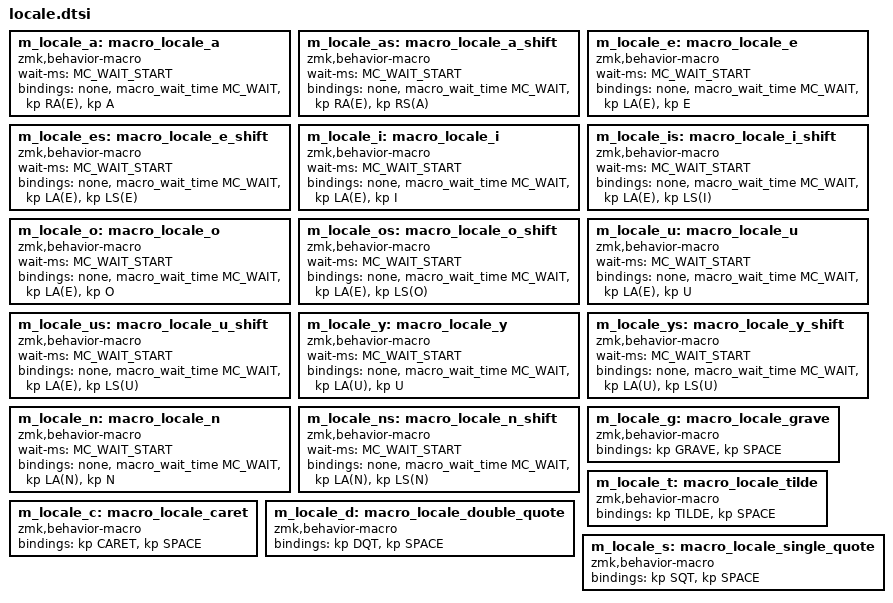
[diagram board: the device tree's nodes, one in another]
// action:     á
m_locale_a: macro_locale_a {
    compatible = "zmk,behavior-macro";
    #binding-cells = <0>;
    wait-ms = <MC_WAIT_START>;
    bindings
        = <&none>
        , <&macro_wait_time MC_WAIT>
        , <&kp RA(E)>
        , <&kp A>;
};

// action:     Á
m_locale_as: macro_locale_a_shift {
    compatible = "zmk,behavior-macro";
    #binding-cells = <0>;
    wait-ms = <MC_WAIT_START>;
    bindings
        = <&none>
        , <&macro_wait_time MC_WAIT>
        , <&kp RA(E)>
        , <&kp RS(A)>;
};

// action:     é
m_locale_e: macro_locale_e {
    compatible = "zmk,behavior-macro";
    #binding-cells = <0>;
    wait-ms = <MC_WAIT_START>;
    bindings
        = <&none>
        , <&macro_wait_time MC_WAIT>
        , <&kp LA(E)>
        , <&kp E>;
};

// action:     É
m_locale_es: macro_locale_e_shift {
    compatible = "zmk,behavior-macro";
    #binding-cells = <0>;
    wait-ms = <MC_WAIT_START>;
    bindings
        = <&none>
        , <&macro_wait_time MC_WAIT>
        , <&kp LA(E)>
        , <&kp LS(E)>;
};

// action:     í
m_locale_i: macro_locale_i {
    compatible = "zmk,behavior-macro";
    #binding-cells = <0>;
    wait-ms = <MC_WAIT_START>;
    bindings
        = <&none>
        , <&macro_wait_time MC_WAIT>
        , <&kp LA(E)>
        , <&kp I>;
};

// action:     Í
m_locale_is: macro_locale_i_shift {
    compatible = "zmk,behavior-macro";
    #binding-cells = <0>;
    wait-ms = <MC_WAIT_START>;
    bindings
        = <&none>
        , <&macro_wait_time MC_WAIT>
        , <&kp LA(E)>
        , <&kp LS(I)>;
};

// action:     ó
m_locale_o: macro_locale_o {
    compatible = "zmk,behavior-macro";
    #binding-cells = <0>;
    wait-ms = <MC_WAIT_START>;
    bindings
        = <&none>
        , <&macro_wait_time MC_WAIT>
        , <&kp LA(E)>
        , <&kp O>;
};

// action:     Ó
m_locale_os: macro_locale_o_shift {
    compatible = "zmk,behavior-macro";
    #binding-cells = <0>;
    wait-ms = <MC_WAIT_START>;
    bindings
        = <&none>
        , <&macro_wait_time MC_WAIT>
        , <&kp LA(E)>
        , <&kp LS(O)>;
};

// action:     ú
m_locale_u: macro_locale_u {
    compatible = "zmk,behavior-macro";
    #binding-cells = <0>;
    wait-ms = <MC_WAIT_START>;
    bindings
        = <&none>
        , <&macro_wait_time MC_WAIT>
        , <&kp LA(E)>
        , <&kp U>;
};

// action:     Ú
m_locale_us: macro_locale_u_shift {
    compatible = "zmk,behavior-macro";
    #binding-cells = <0>;
    wait-ms = <MC_WAIT_START>;

    bindings
        = <&none>
        , <&macro_wait_time MC_WAIT>
        , <&kp LA(E)>
        , <&kp LS(U)>;
};

// action:     ü
m_locale_y: macro_locale_y {
    compatible = "zmk,behavior-macro";
    #binding-cells = <0>;
    wait-ms = <MC_WAIT_START>;
    bindings
        = <&none>
        , <&macro_wait_time MC_WAIT>
        , <&kp LA(U)>
        , <&kp U>;
};

// action:     Ü
m_locale_ys: macro_locale_y_shift {
    compatible = "zmk,behavior-macro";
    #binding-cells = <0>;
    wait-ms = <MC_WAIT_START>;
    bindings
        = <&none>
        , <&macro_wait_time MC_WAIT>
        , <&kp LA(U)>
        , <&kp LS(U)>;
};

// action:     ñ
m_locale_n: macro_locale_n {
    compatible = "zmk,behavior-macro";
    #binding-cells = <0>;
    wait-ms = <MC_WAIT_START>;
    bindings
        = <&none>
        , <&macro_wait_time MC_WAIT>
        , <&kp LA(N)>
        , <&kp N>;
};

// action:     Ñ
m_locale_ns: macro_locale_n_shift {
    compatible = "zmk,behavior-macro";
    #binding-cells = <0>;
    wait-ms = <MC_WAIT_START>;
    bindings
        = <&none>
        , <&macro_wait_time MC_WAIT>
        , <&kp LA(N)>
        , <&kp LS(N)>;
};

// action:  `
m_locale_g: macro_locale_grave {
    compatible = "zmk,behavior-macro";
    #binding-cells = <0>;
    bindings =
        <&kp GRAVE &kp SPACE>;
};

// action:  ~
m_locale_t: macro_locale_tilde {
    compatible = "zmk,behavior-macro";
    #binding-cells = <0>;
    bindings =
        <&kp TILDE &kp SPACE>;
};

// action:  ^
m_locale_c: macro_locale_caret {
    compatible = "zmk,behavior-macro";
    #binding-cells = <0>;
    bindings =
        <&kp CARET &kp SPACE>;
};

// action:  "
m_locale_d: macro_locale_double_quote {
    compatible = "zmk,behavior-macro";
    #binding-cells = <0>;
    bindings =
        <&kp DQT &kp SPACE>;
};

// action:  '
m_locale_s: macro_locale_single_quote {
    compatible = "zmk,behavior-macro";
    #binding-cells = <0>;
    bindings =
        <&kp SQT &kp SPACE>;
};
